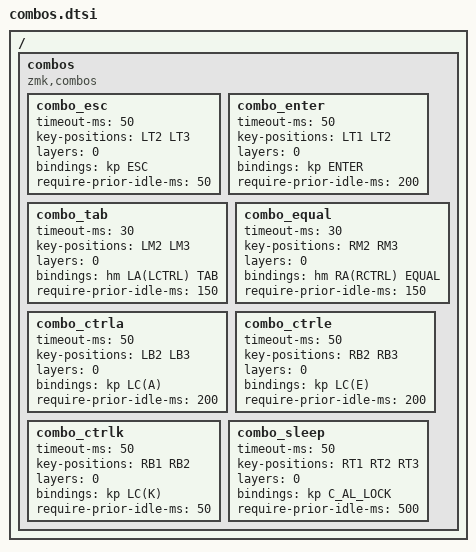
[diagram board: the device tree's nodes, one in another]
/*
						KEY POSITIONS
  ╭────────────────────────╮ ╭────────────────────────╮
  │LT5 LT4 LT3 LT2 LT1 LT0 │ │ RT0 RT1 RT2 RT3 RT4 RT5│
  │LM5 LM4 LM3 LM2 LM1 LM0 │ │ RM0 RM1 RM2 RM3 RM4 RM5│
  │LB5 LB4 LB3 LB2 LB1 LB0 │ │ RB0 RB1 RB2 RB3 RB4 RB5│
  ╰──────────╮ LH2 LH1 LH0 │ │ RH0 RH1 RH2 ╭──────────╯
             ╰─────────────╯ ╰─────────────╯ 
*/

/ {

    combos {
        compatible = "zmk,combos";

        combo_esc {
            timeout-ms = <50>;  // all keys must be pressed within 'timeout-ms'
            key-positions = <LT2 LT3>;
            // global-quick-tap-ms = <75>;
            layers = <0>;
            bindings = <&kp ESC>;
            require-prior-idle-ms = <50>;
        };

        combo_enter {
            timeout-ms = <50>;
            key-positions = <LT1 LT2>;
            // global-quick-tap-ms = <75>;
            layers = <0>;
            bindings = <&kp ENTER>;
            require-prior-idle-ms = <200>;
        };

        combo_tab {
            timeout-ms = <30>;
            key-positions = <LM2 LM3>;
            layers = <0>;
            bindings = <&hm LA(LCTRL) TAB>;
            require-prior-idle-ms = <150>;
        };

        combo_equal {
            timeout-ms = <30>;
            key-positions = <RM2 RM3>;
            layers = <0>;
            bindings = <&hm RA(RCTRL) EQUAL>;
            require-prior-idle-ms = <150>;
        };

        combo_ctrla {
            timeout-ms = <50>;
            key-positions = <LB2 LB3>;
            layers = <0>;
            bindings = <&kp LC(A)>;
            require-prior-idle-ms = <200>;
        };

        combo_ctrle {
            timeout-ms = <50>;
            key-positions = <RB2 RB3>;
            layers = <0>;
            bindings = <&kp LC(E)>;
            require-prior-idle-ms = <200>;
        };

        combo_ctrlk {
            timeout-ms = <50>;  
            key-positions = <RB1 RB2>;
            layers = <0>;
            bindings = <&kp LC(K)>;
            require-prior-idle-ms = <50>;
		};

        combo_sleep {
            timeout-ms = <50>;
            key-positions = <RT1 RT2 RT3>;
            layers = <0>;
            bindings = <&kp C_AL_LOCK>;
            require-prior-idle-ms = <500>;
        };
        
    };
};


/* 
	Unused combos:
			
		combo_repeat_left {
            timeout-ms = <100>;  
            key-positions = <LB1 LB2>;
            layers = <0>;
            bindings = <&key_repeat>;
            require-prior-idle-ms = <50>;
		};

         combo_underscore {
            timeout-ms = <30>;
            key-positions = <RM1 RM2>;
            // global-quick-tap-ms = <75>;
            layers = <0>;
            bindings = <&kp UNDER>;
            require-prior-idle-ms = <300>;
        };
			   
         combo_hyphen {
            timeout-ms = <30>;
            key-positions = <LM1 LM2>;
            // global-quick-tap-ms = <75>;
            layers = <0>;
            bindings = <&kp MINUS>;
            require-prior-idle-ms = <300>;
        };

*/ 
